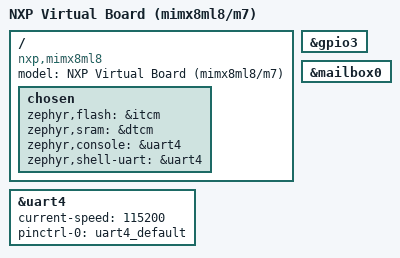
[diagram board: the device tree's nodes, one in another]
/* Auto-generated by gen_nxp_virtual_board.py */
/* Master DTS template: boards/nxp/imx8mp_evk/imx8mp_evk_mimx8ml8_m7.dts */
/*
 * Copyright (c) 2021, Laird Connectivity
 *
 * SPDX-License-Identifier: Apache-2.0
 */

/dts-v1/;

#include <nxp/nxp_imx8ml_m7.dtsi>
#include "imx8mp_evk-pinctrl.dtsi"

/ {
	model = "NXP Virtual Board (mimx8ml8/m7)";
	compatible = "nxp,mimx8ml8";

	chosen {
		/* TCM */
		zephyr,flash = &itcm;
		zephyr,sram = &dtcm;

		zephyr,console = &uart4;
		zephyr,shell-uart = &uart4;
	};
};

&uart4 {
	status = "okay";
	current-speed = <115200>;
	pinctrl-0 = <&uart4_default>;
	pinctrl-names = "default";
};

&gpio3 {
	status = "okay";
};

&mailbox0 {
	status = "okay";
};
